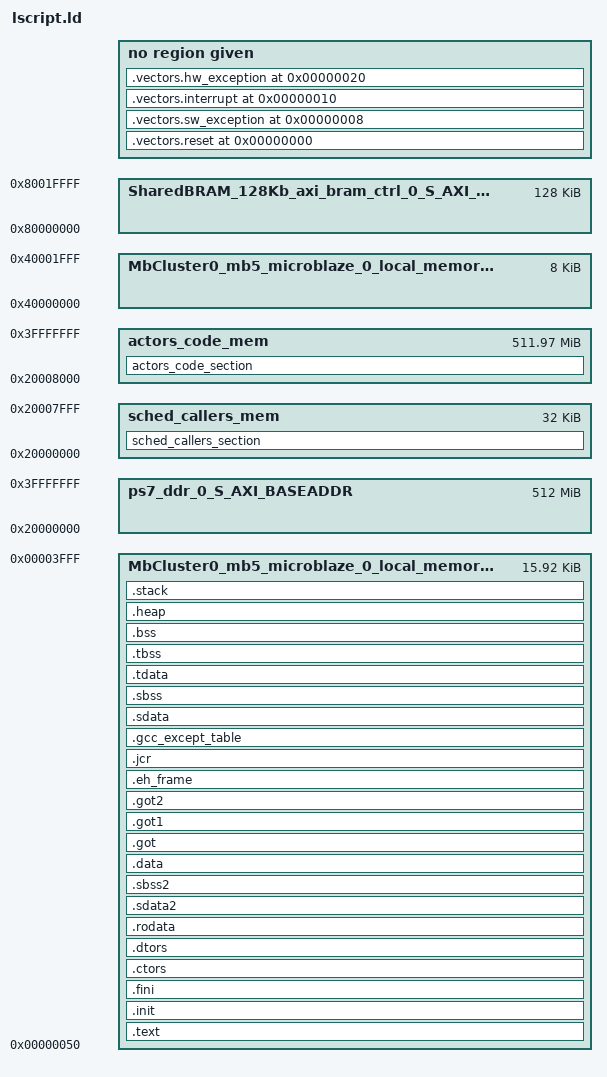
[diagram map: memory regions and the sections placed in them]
/*******************************************************************/
/*                                                                 */
/* This file is automatically generated by linker script generator.*/
/*                                                                 */
/* Version:                                 */
/*                                                                 */
/* Copyright (c) 2010 Xilinx, Inc.  All rights reserved.           */
/*                                                                 */
/* Description : MicroBlaze Linker Script                          */
/*                                                                 */
/*******************************************************************/

_STACK_SIZE = DEFINED(_STACK_SIZE) ? _STACK_SIZE : 0x400;
_HEAP_SIZE = DEFINED(_HEAP_SIZE) ? _HEAP_SIZE : 0x400;

/* Define Memories in the system */

MEMORY
{
   ps7_ddr_0_S_AXI_BASEADDR : ORIGIN = 0x20000000, LENGTH = 0x20000000
   MbCluster0_mb5_microblaze_0_local_memory_lmb_bram_cntlr_0_MbCluster0_mb5_microblaze_0_local_memory_lmb_bram_cntlr_1 : ORIGIN = 0x00000050, LENGTH = 0x00003FB0
   MbCluster0_mb5_microblaze_0_local_memory_lmb_bram_cntlr_2 : ORIGIN = 0x40000000, LENGTH = 0x00002000
   SharedBRAM_128Kb_axi_bram_ctrl_0_S_AXI_BASEADDR : ORIGIN = 0x80000000, LENGTH = 0x00020000
   sched_callers_mem  : ORIGIN = 0x20000000, LENGTH = 0x8000
   actors_code_mem  : ORIGIN = 0x20008000, LENGTH = 0x1fff8000
}

/* Specify the default entry point to the program */

ENTRY(_start)

/* Define the sections, and where they are mapped in memory */

SECTIONS
{
.vectors.reset 0x00000000 : {
   KEEP (*(.vectors.reset))
} 

.vectors.sw_exception 0x00000008 : {
   KEEP (*(.vectors.sw_exception))
} 

.vectors.interrupt 0x00000010 : {
   KEEP (*(.vectors.interrupt))
} 

.vectors.hw_exception 0x00000020 : {
   KEEP (*(.vectors.hw_exception))
} 

sched_callers_section (NOLOAD): {
   *schedCallers.o
} > sched_callers_mem

actors_code_section (NOLOAD): {
	*libActors.a:*
} > actors_code_mem

.text : {
   *(.text)
   *(.text.*)
   *(.gnu.linkonce.t.*)
} > MbCluster0_mb5_microblaze_0_local_memory_lmb_bram_cntlr_0_MbCluster0_mb5_microblaze_0_local_memory_lmb_bram_cntlr_1

.init : {
   KEEP (*(.init))
} > MbCluster0_mb5_microblaze_0_local_memory_lmb_bram_cntlr_0_MbCluster0_mb5_microblaze_0_local_memory_lmb_bram_cntlr_1

.fini : {
   KEEP (*(.fini))
} > MbCluster0_mb5_microblaze_0_local_memory_lmb_bram_cntlr_0_MbCluster0_mb5_microblaze_0_local_memory_lmb_bram_cntlr_1

.ctors : {
   __CTOR_LIST__ = .;
   ___CTORS_LIST___ = .;
   KEEP (*crtbegin.o(.ctors))
   KEEP (*(EXCLUDE_FILE(*crtend.o) .ctors))
   KEEP (*(SORT(.ctors.*)))
   KEEP (*(.ctors))
   __CTOR_END__ = .;
   ___CTORS_END___ = .;
} > MbCluster0_mb5_microblaze_0_local_memory_lmb_bram_cntlr_0_MbCluster0_mb5_microblaze_0_local_memory_lmb_bram_cntlr_1

.dtors : {
   __DTOR_LIST__ = .;
   ___DTORS_LIST___ = .;
   KEEP (*crtbegin.o(.dtors))
   KEEP (*(EXCLUDE_FILE(*crtend.o) .dtors))
   KEEP (*(SORT(.dtors.*)))
   KEEP (*(.dtors))
   PROVIDE(__DTOR_END__ = .);
   PROVIDE(___DTORS_END___ = .);
} > MbCluster0_mb5_microblaze_0_local_memory_lmb_bram_cntlr_0_MbCluster0_mb5_microblaze_0_local_memory_lmb_bram_cntlr_1

.rodata : {
   __rodata_start = .;
   *(.rodata)
   *(.rodata.*)
   *(.gnu.linkonce.r.*)
   __rodata_end = .;
} > MbCluster0_mb5_microblaze_0_local_memory_lmb_bram_cntlr_0_MbCluster0_mb5_microblaze_0_local_memory_lmb_bram_cntlr_1

.sdata2 : {
   . = ALIGN(8);
   __sdata2_start = .;
   *(.sdata2)
   *(.sdata2.*)
   *(.gnu.linkonce.s2.*)
   . = ALIGN(8);
   __sdata2_end = .;
} > MbCluster0_mb5_microblaze_0_local_memory_lmb_bram_cntlr_0_MbCluster0_mb5_microblaze_0_local_memory_lmb_bram_cntlr_1

.sbss2 : {
   __sbss2_start = .;
   *(.sbss2)
   *(.sbss2.*)
   *(.gnu.linkonce.sb2.*)
   __sbss2_end = .;
} > MbCluster0_mb5_microblaze_0_local_memory_lmb_bram_cntlr_0_MbCluster0_mb5_microblaze_0_local_memory_lmb_bram_cntlr_1

.data : {
   . = ALIGN(4);
   __data_start = .;
   *(.data)
   *(.data.*)
   *(.gnu.linkonce.d.*)
   __data_end = .;
} > MbCluster0_mb5_microblaze_0_local_memory_lmb_bram_cntlr_0_MbCluster0_mb5_microblaze_0_local_memory_lmb_bram_cntlr_1

.got : {
   *(.got)
} > MbCluster0_mb5_microblaze_0_local_memory_lmb_bram_cntlr_0_MbCluster0_mb5_microblaze_0_local_memory_lmb_bram_cntlr_1

.got1 : {
   *(.got1)
} > MbCluster0_mb5_microblaze_0_local_memory_lmb_bram_cntlr_0_MbCluster0_mb5_microblaze_0_local_memory_lmb_bram_cntlr_1

.got2 : {
   *(.got2)
} > MbCluster0_mb5_microblaze_0_local_memory_lmb_bram_cntlr_0_MbCluster0_mb5_microblaze_0_local_memory_lmb_bram_cntlr_1

.eh_frame : {
   *(.eh_frame)
} > MbCluster0_mb5_microblaze_0_local_memory_lmb_bram_cntlr_0_MbCluster0_mb5_microblaze_0_local_memory_lmb_bram_cntlr_1

.jcr : {
   *(.jcr)
} > MbCluster0_mb5_microblaze_0_local_memory_lmb_bram_cntlr_0_MbCluster0_mb5_microblaze_0_local_memory_lmb_bram_cntlr_1

.gcc_except_table : {
   *(.gcc_except_table)
} > MbCluster0_mb5_microblaze_0_local_memory_lmb_bram_cntlr_0_MbCluster0_mb5_microblaze_0_local_memory_lmb_bram_cntlr_1

.sdata : {
   . = ALIGN(8);
   __sdata_start = .;
   *(.sdata)
   *(.sdata.*)
   *(.gnu.linkonce.s.*)
   __sdata_end = .;
} > MbCluster0_mb5_microblaze_0_local_memory_lmb_bram_cntlr_0_MbCluster0_mb5_microblaze_0_local_memory_lmb_bram_cntlr_1

.sbss (NOLOAD) : {
   . = ALIGN(4);
   __sbss_start = .;
   *(.sbss)
   *(.sbss.*)
   *(.gnu.linkonce.sb.*)
   . = ALIGN(8);
   __sbss_end = .;
} > MbCluster0_mb5_microblaze_0_local_memory_lmb_bram_cntlr_0_MbCluster0_mb5_microblaze_0_local_memory_lmb_bram_cntlr_1

.tdata : {
   __tdata_start = .;
   *(.tdata)
   *(.tdata.*)
   *(.gnu.linkonce.td.*)
   __tdata_end = .;
} > MbCluster0_mb5_microblaze_0_local_memory_lmb_bram_cntlr_0_MbCluster0_mb5_microblaze_0_local_memory_lmb_bram_cntlr_1

.tbss : {
   __tbss_start = .;
   *(.tbss)
   *(.tbss.*)
   *(.gnu.linkonce.tb.*)
   __tbss_end = .;
} > MbCluster0_mb5_microblaze_0_local_memory_lmb_bram_cntlr_0_MbCluster0_mb5_microblaze_0_local_memory_lmb_bram_cntlr_1

.bss (NOLOAD) : {
   . = ALIGN(4);
   __bss_start = .;
   *(.bss)
   *(.bss.*)
   *(.gnu.linkonce.b.*)
   *(COMMON)
   . = ALIGN(4);
   __bss_end = .;
} > MbCluster0_mb5_microblaze_0_local_memory_lmb_bram_cntlr_0_MbCluster0_mb5_microblaze_0_local_memory_lmb_bram_cntlr_1

_SDA_BASE_ = __sdata_start + ((__sbss_end - __sdata_start) / 2 );

_SDA2_BASE_ = __sdata2_start + ((__sbss2_end - __sdata2_start) / 2 );

/* Generate Stack and Heap definitions */

.heap (NOLOAD) : {
   . = ALIGN(8);
   _heap = .;
   _heap_start = .;
   . += _HEAP_SIZE;
   _heap_end = .;
} > MbCluster0_mb5_microblaze_0_local_memory_lmb_bram_cntlr_0_MbCluster0_mb5_microblaze_0_local_memory_lmb_bram_cntlr_1

.stack (NOLOAD) : {
   _stack_end = .;
   . += _STACK_SIZE;
   . = ALIGN(8);
   _stack = .;
   __stack = _stack;
} > MbCluster0_mb5_microblaze_0_local_memory_lmb_bram_cntlr_0_MbCluster0_mb5_microblaze_0_local_memory_lmb_bram_cntlr_1

_end = .;
}

